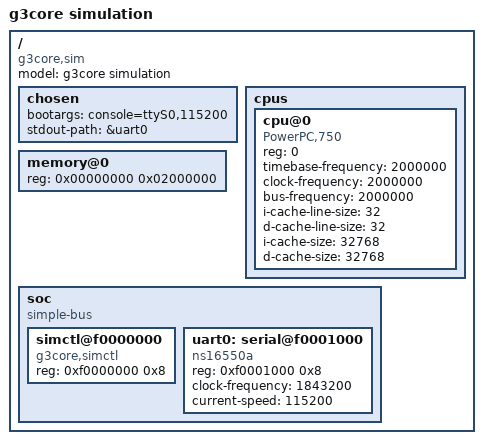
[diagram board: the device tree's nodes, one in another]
/dts-v1/;
/* g3core simulation SoC: 32 MiB RAM, 16550 UART, simulator control register */
/ {
	#address-cells = <1>;
	#size-cells = <1>;
	model = "g3core simulation";
	compatible = "g3core,sim";

	chosen {
		bootargs = "console=ttyS0,115200";
		stdout-path = &uart0;
	};

	cpus {
		#address-cells = <1>;
		#size-cells = <0>;
		cpu@0 {
			device_type = "cpu";
			compatible = "PowerPC,750";
			reg = <0>;
			/* in simulation the time base counts executed instructions */
			timebase-frequency = <2000000>;
			clock-frequency = <2000000>;
			bus-frequency = <2000000>;
			i-cache-line-size = <32>;
			d-cache-line-size = <32>;
			i-cache-size = <32768>;
			d-cache-size = <32768>;
		};
	};

	memory@0 {
		device_type = "memory";
		reg = <0x00000000 0x02000000>;
	};

	soc {
		compatible = "simple-bus";
		#address-cells = <1>;
		#size-cells = <1>;
		ranges;

		simctl@f0000000 {
			compatible = "g3core,simctl";
			reg = <0xf0000000 0x8>;
		};

		uart0: serial@f0001000 {
			device_type = "serial";
			compatible = "ns16550a", "ns16550";
			reg = <0xf0001000 0x8>;
			clock-frequency = <1843200>;
			current-speed = <115200>;
		};
	};
};
